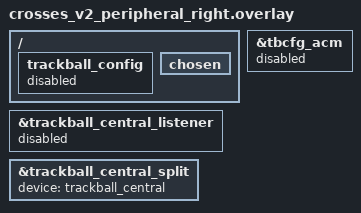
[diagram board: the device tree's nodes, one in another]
/* Turn off the local central listener, trackball events should not stay here */
&trackball_central_listener {
    status = "disabled";
};

/* Turn ON the split relay node for the right ball and point it to the local sensor */
&trackball_central_split {
    status = "okay";
    device = <&trackball_central>;
};

/* Disable trackball config so it doesn't fail building on the peripheral */
/ {
    trackball_config {
        status = "disabled";
    };
    chosen {
        /delete-property/ gggw,trackball-config-uart;
    };
};

&tbcfg_acm {
    status = "disabled";
};
